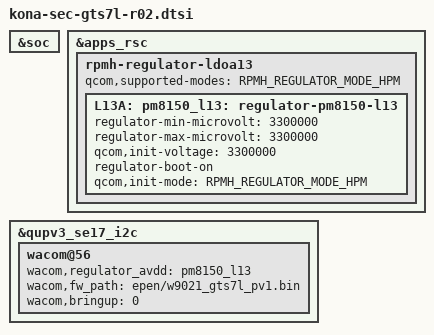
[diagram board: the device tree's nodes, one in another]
/* Copyright (c) 2020, The Linux Foundation. All rights reserved.
 *
 * This program is free software; you can redistribute it and/or modify
 * it under the terms of the GNU General Public License version 2 and
 * only version 2 as published by the Free Software Foundation.
 *
 * This program is distributed in the hope that it will be useful,
 * but WITHOUT ANY WARRANTY; without even the implied warranty of
 * MERCHANTABILITY or FITNESS FOR A PARTICULAR PURPOSE.  See the
 * GNU General Public License for more details.
 */

#include "kona-sec-gts7l-r01.dtsi"
#include "kona-sec-gts7l-pinctrl-r02.dtsi"

/delete-node/ &vdd_spen_3p3;

&soc {
    
};

&apps_rsc {
	rpmh-regulator-ldoa13 {
		qcom,supported-modes = <RPMH_REGULATOR_MODE_HPM>;
		L13A: pm8150_l13: regulator-pm8150-l13 {
			regulator-min-microvolt = <3300000>;
			regulator-max-microvolt = <3300000>;
			qcom,init-voltage = <3300000>;
			regulator-boot-on;
			qcom,init-mode = <RPMH_REGULATOR_MODE_HPM>;
		};
	};
};

&qupv3_se17_i2c {
	wacom@56 {
		wacom,regulator_avdd = "pm8150_l13";
		wacom,fw_path = "epen/w9021_gts7l_pv1.bin";
		wacom,bringup = <0>;
	};
};

